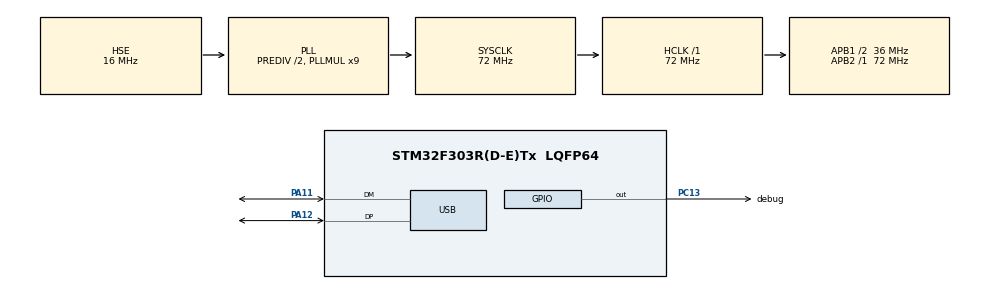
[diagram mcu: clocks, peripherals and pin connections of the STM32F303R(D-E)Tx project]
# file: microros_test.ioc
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FREERTOS.Tasks01=defaultTask,0,128,StartDefaultTask,Default,NULL,Dynamic,NULL,NULL
Mcu.Family=STM32F3
Mcu.Name=STM32F303R(D-E)Tx
Mcu.Package=LQFP64
NVIC.PriorityGroup=NVIC_PRIORITYGROUP_4
NVIC.USB_LP_CAN_RX0_IRQn=true\:5\:0\:false\:false\:true\:true\:false\:true\:true
PA11.Mode=Device
PA11.Signal=USB_DM
PA12.Mode=Device
PA12.Signal=USB_DP
PC13.GPIO_Label=debug
PC13.Signal=GPIO_Output
PF0-OSC_IN.Mode=HSE-External-Oscillator
PF0-OSC_IN.Signal=RCC_OSC_IN
PF1-OSC_OUT.Mode=HSE-External-Oscillator
PF1-OSC_OUT.Signal=RCC_OSC_OUT
ProjectManager.HeapSize=0x200
ProjectManager.StackSize=0x400
ProjectManager.TargetToolchain=STM32CubeIDE
RCC.AHBFreq_Value=72000000
RCC.APB1CLKDivider=RCC_HCLK_DIV2
RCC.APB1Freq_Value=36000000
RCC.APB1TimFreq_Value=72000000
RCC.APB2Freq_Value=72000000
RCC.APB2TimFreq_Value=72000000
RCC.CortexFreq_Value=72000000
RCC.HCLKFreq_Value=72000000
RCC.HSE_VALUE=16000000
RCC.HSI_VALUE=8000000
RCC.LSE_VALUE=32768
RCC.PLLDivider=RCC_PREDIV_DIV2
RCC.PLLMUL=RCC_PLL_MUL9
RCC.PRESCALERUSB=RCC_USBCLKSOURCE_PLL_DIV1_5
RCC.SYSCLKFreq_VALUE=72000000
RCC.SYSCLKSourceVirtual=RCC_SYSCLKSOURCE_PLLCLK
RCC.USBFreq_Value=48000000
USB_DEVICE.CLASS_NAME_FS=CDC
USB_DEVICE.VirtualMode=Cdc
USB_DEVICE.VirtualModeFS=Cdc_FS
VP_FREERTOS_VS_CMSIS_V1.Mode=CMSIS_V1
VP_USB_DEVICE_VS_USB_DEVICE_CDC_FS.Mode=CDC_FS
board=custom

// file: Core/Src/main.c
/* USER CODE BEGIN Header */
/**
  ******************************************************************************
  * @file           : main.c
  * @brief          : Main program body
  ******************************************************************************
  * @attention
  *
  * Copyright (c) 2026 STMicroelectronics.
  * All rights reserved.
  *
  * This software is licensed under terms that can be found in the LICENSE file
  * in the root directory of this software component.
  * If no LICENSE file comes with this software, it is provided AS-IS.
  *
  ******************************************************************************
  */
/* USER CODE END Header */
#include "main.h"
#include "cmsis_os.h"
#include "usb_device.h"
#include "gpio.h"

void SystemClock_Config(void);
void MX_FREERTOS_Init(void);

int main(void)
{

  /* MCU Configuration--------------------------------------------------------*/

  /* Reset of all peripherals, Initializes the Flash interface and the Systick. */
  HAL_Init();

  /* Configure the system clock */
  SystemClock_Config();

  /* Initialize all configured peripherals */
  MX_GPIO_Init();

  /* Call init function for freertos objects (in cmsis_os2.c) */
  MX_FREERTOS_Init();

  /* Start scheduler */
  osKernelStart();

  /* We should never get here as control is now taken by the scheduler */

  /* Infinite loop */
  while (1)
  {

  }
}

void SystemClock_Config(void)
{
  RCC_OscInitTypeDef RCC_OscInitStruct = {0};
  RCC_ClkInitTypeDef RCC_ClkInitStruct = {0};
  RCC_PeriphCLKInitTypeDef PeriphClkInit = {0};

  /** Initializes the RCC Oscillators according to the specified parameters
  * in the RCC_OscInitTypeDef structure.
  */
  RCC_OscInitStruct.OscillatorType = RCC_OSCILLATORTYPE_HSE;
  RCC_OscInitStruct.HSEState = RCC_HSE_ON;
  RCC_OscInitStruct.HSIState = RCC_HSI_ON;
  RCC_OscInitStruct.PLL.PLLState = RCC_PLL_ON;
  RCC_OscInitStruct.PLL.PLLSource = RCC_PLLSOURCE_HSE;
  RCC_OscInitStruct.PLL.PLLMUL = RCC_PLL_MUL9;
  RCC_OscInitStruct.PLL.PREDIV = RCC_PREDIV_DIV2;
  if (HAL_RCC_OscConfig(&RCC_OscInitStruct) != HAL_OK)
  {
    Error_Handler();
  }

  /** Initializes the CPU, AHB and APB buses clocks
  */
  RCC_ClkInitStruct.ClockType = RCC_CLOCKTYPE_HCLK|RCC_CLOCKTYPE_SYSCLK
                              |RCC_CLOCKTYPE_PCLK1|RCC_CLOCKTYPE_PCLK2;
  RCC_ClkInitStruct.SYSCLKSource = RCC_SYSCLKSOURCE_PLLCLK;
  RCC_ClkInitStruct.AHBCLKDivider = RCC_SYSCLK_DIV1;
  RCC_ClkInitStruct.APB1CLKDivider = RCC_HCLK_DIV2;
  RCC_ClkInitStruct.APB2CLKDivider = RCC_HCLK_DIV1;

  if (HAL_RCC_ClockConfig(&RCC_ClkInitStruct, FLASH_LATENCY_2) != HAL_OK)
  {
    Error_Handler();
  }
  PeriphClkInit.PeriphClockSelection = RCC_PERIPHCLK_USB;
  PeriphClkInit.USBClockSelection = RCC_USBCLKSOURCE_PLL_DIV1_5;
  if (HAL_RCCEx_PeriphCLKConfig(&PeriphClkInit) != HAL_OK)
  {
    Error_Handler();
  }
}

void Error_Handler(void)
{
  /* USER CODE BEGIN Error_Handler_Debug */
  /* User can add his own implementation to report the HAL error return state */
  __disable_irq();
  while (1)
  {
	  HAL_GPIO_WritePin(debug_GPIO_Port, debug_Pin, GPIO_PIN_SET);
  }
  /* USER CODE END Error_Handler_Debug */
}

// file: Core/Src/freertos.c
/* USER CODE BEGIN Header */
/**
  ******************************************************************************
  * File Name          : freertos.c
  * Description        : Code for freertos applications
  ******************************************************************************
  * @attention
  *
  * Copyright (c) 2026 STMicroelectronics.
  * All rights reserved.
  *
  * This software is licensed under terms that can be found in the LICENSE file
  * in the root directory of this software component.
  * If no LICENSE file comes with this software, it is provided AS-IS.
  *
  ******************************************************************************
  */
/* USER CODE END Header */

#include "FreeRTOS.h"
#include "task.h"
#include "main.h"
#include "cmsis_os.h"

/* USER CODE BEGIN Includes */
#include <rcl/rcl.h>
#include <rcl/error_handling.h>
#include <rclc/rclc.h>
#include <rclc/executor.h>
#include <std_msgs/msg/int32.h>
#include <std_msgs/msg/float32.h>
#include <rmw_microros/rmw_microros.h>
#include "usb_cdc_transport.h"
#include "usbd_cdc_if.h"
#include <std_msgs/msg/float32_multi_array.h>
#include <std_msgs/msg/int32_multi_array.h>
#include <geometry_msgs/msg/twist.h>

/* USER CODE END Includes */

/* USER CODE BEGIN PTD */
extern USBD_HandleTypeDef hUsbDeviceFS;

/* USER CODE END PTD */

/* USER CODE BEGIN PD */
void cmd_vel_callback(const void * msgin);

/* USER CODE END PD */

/* USER CODE BEGIN Variables */
rcl_node_t node;
rclc_support_t support;
rcl_publisher_t motor_pub;
rcl_publisher_t encoder_pub;
rclc_executor_t executor;
rcl_subscription_t cmd_vel_sub;
geometry_msgs__msg__Twist cmd_vel_msg;

/* Messages */
std_msgs__msg__Float32MultiArray motor_msg;
std_msgs__msg__Int32MultiArray encoder_msg;

/* Static data buffers (NO dynamic alloc!) */
float motor_data[3];
int32_t encoder_data[3];
/* USER CODE END Variables */
osThreadId defaultTaskHandle;

void StartDefaultTask(void const * argument);

extern void MX_USB_DEVICE_Init(void);
void MX_FREERTOS_Init(void); /* (MISRA C 2004 rule 8.1) */

/* GetIdleTaskMemory prototype (linked to static allocation support) */
void vApplicationGetIdleTaskMemory( StaticTask_t **ppxIdleTaskTCBBuffer, StackType_t **ppxIdleTaskStackBuffer, uint32_t *pulIdleTaskStackSize );

/* USER CODE BEGIN GET_IDLE_TASK_MEMORY */
static StaticTask_t xIdleTaskTCBBuffer;
static StackType_t xIdleStack[configMINIMAL_STACK_SIZE];

void vApplicationGetIdleTaskMemory( StaticTask_t **ppxIdleTaskTCBBuffer, StackType_t **ppxIdleTaskStackBuffer, uint32_t *pulIdleTaskStackSize )
{
  *ppxIdleTaskTCBBuffer = &xIdleTaskTCBBuffer;
  *ppxIdleTaskStackBuffer = &xIdleStack[0];
  *pulIdleTaskStackSize = configMINIMAL_STACK_SIZE;
  /* place for user code */
}
/* USER CODE END GET_IDLE_TASK_MEMORY */

void MX_FREERTOS_Init(void) {

  /* Create the thread(s) */
  /* definition and creation of defaultTask */
  osThreadDef(defaultTask, StartDefaultTask, osPriorityNormal, 0, 2048);
  defaultTaskHandle = osThreadCreate(osThread(defaultTask), NULL);

}

void StartDefaultTask(void const * argument)
{
    /* --- USB CDC init --- */
    MX_USB_DEVICE_Init();
    osDelay(2000);

    /* --- Set custom transport --- */
    rmw_uros_set_custom_transport(
        true,
        NULL,
        cubemx_transport_open,
        cubemx_transport_close,
        cubemx_transport_write,
		cubemx_transport_read);

    rcl_allocator_t allocator = rcl_get_default_allocator();

    /* --- Init support --- */
    if (rclc_support_init(&support, 0, NULL, &allocator) != RCL_RET_OK) {
        Error_Handler();
    }

    /* --- Create node --- */
    while (rmw_uros_ping_agent(100, 1) != RMW_RET_OK)
    {
        // Toggle LED to indicate waiting for agent
        HAL_GPIO_TogglePin(debug_GPIO_Port, debug_Pin);
        osDelay(100);
    }

    /* --- Create node --- */
    if (rclc_node_init_default(&node, "mcu", "", &support) != RCL_RET_OK) {
        Error_Handler();
    }
    if (rclc_subscription_init_best_effort(
            &cmd_vel_sub,
            &node,
            ROSIDL_GET_MSG_TYPE_SUPPORT(geometry_msgs, msg, Twist),
            "/cmd_vel") != RCL_RET_OK)
    {
        Error_Handler();
    }

    /* --- Init publishers --- */
    if (rclc_publisher_init_best_effort(
            &motor_pub,
            &node,
            ROSIDL_GET_MSG_TYPE_SUPPORT(std_msgs, msg, Float32MultiArray),
            "/motors/current") != RCL_RET_OK) {

        Error_Handler();
    }

    if (rclc_publisher_init_best_effort(
            &encoder_pub,
            &node,
            ROSIDL_GET_MSG_TYPE_SUPPORT(std_msgs, msg, Int32MultiArray),
            "/encoders/absolute") != RCL_RET_OK) {

        Error_Handler();
    }

    executor = rclc_executor_get_zero_initialized_executor();
    rclc_executor_init(&executor, &support.context, 1, &allocator);

    rclc_executor_add_subscription(
        &executor,
        &cmd_vel_sub,
        &cmd_vel_msg,
        &cmd_vel_callback,
        ON_NEW_DATA);

    motor_msg.data.data = motor_data;
    motor_msg.data.size = 3;
    motor_msg.data.capacity = 3;

    encoder_msg.data.data = encoder_data;
    encoder_msg.data.size = 3;
    encoder_msg.data.capacity = 3;

    int32_t enc1 = 0, enc2 = 0, enc3 = 0;

    for(;;)
    {
        motor_data[0] = ((float)rand() / (float)RAND_MAX) * 10.0f;
        motor_data[1] = ((float)rand() / (float)RAND_MAX) * 10.0f;
        motor_data[2] = ((float)rand() / (float)RAND_MAX) * 10.0f;

        encoder_data[0] = enc1;
        encoder_data[1] = enc2;
        encoder_data[2] = enc3;

        rcl_publish(&motor_pub, &motor_msg, NULL);
        rcl_publish(&encoder_pub, &encoder_msg, NULL);

        rclc_executor_spin_some(&executor, RCL_MS_TO_NS(10));

        enc1 = (enc1 + 5) % 8192;
        enc2 = (enc2 + 3) % 8192;
        enc3 = (enc3 + 7) % 8192;

        osDelay(10);
    }
}

/* USER CODE BEGIN Application */
void cmd_vel_callback(const void * msgin)
{
    const geometry_msgs__msg__Twist * msg = (const geometry_msgs__msg__Twist *)msgin;

    float linear = msg->linear.x;
    float angular = msg->angular.z;

}

/* USER CODE END Application */
